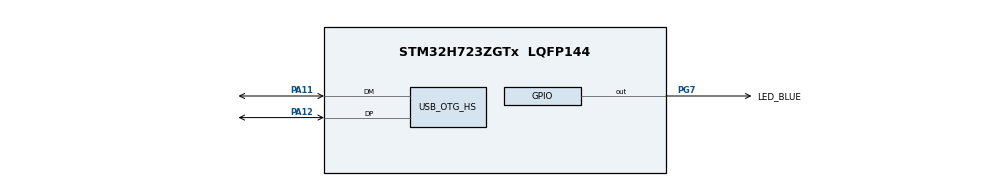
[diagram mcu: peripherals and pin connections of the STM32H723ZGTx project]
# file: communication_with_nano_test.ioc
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CORTEX_M7.default_mode_Activation=1
Mcu.Family=STM32H7
Mcu.Name=STM32H723ZGTx
Mcu.Package=LQFP144
NVIC.OTG_HS_IRQn=true\:0\:0\:false\:false\:true\:true\:true\:true
NVIC.PriorityGroup=NVIC_PRIORITYGROUP_4
NVIC.TIM6_DAC_IRQn=true\:0\:0\:false\:false\:true\:true\:true\:true
PA11.Mode=Device_Only_FS
PA11.Signal=USB_OTG_HS_DM
PA12.Mode=Device_Only_FS
PA12.Signal=USB_OTG_HS_DP
PA13(JTMS/SWDIO).Mode=Serial_Wire
PA13(JTMS/SWDIO).Signal=DEBUG_JTMS-SWDIO
PA14(JTCK/SWCLK).Mode=Serial_Wire
PA14(JTCK/SWCLK).Signal=DEBUG_JTCK-SWCLK
PC14-OSC32_IN.Mode=LSE-External-Oscillator
PC14-OSC32_IN.Signal=RCC_OSC32_IN
PC15-OSC32_OUT.Mode=LSE-External-Oscillator
PC15-OSC32_OUT.Signal=RCC_OSC32_OUT
PG7.GPIO_Label=LED_BLUE
PG7.PinState=GPIO_PIN_SET
PG7.Signal=GPIO_Output
PH0-OSC_IN.Mode=HSE-External-Oscillator
PH0-OSC_IN.Signal=RCC_OSC_IN
PH1-OSC_OUT.Mode=HSE-External-Oscillator
PH1-OSC_OUT.Signal=RCC_OSC_OUT
ProjectManager.HeapSize=0x200
ProjectManager.StackSize=0x400
ProjectManager.TargetToolchain=STM32CubeIDE
RCC.ADCFreq_Value=50390625
RCC.APB1Freq_Value=120000000
RCC.APB2Freq_Value=120000000
RCC.APB3Freq_Value=120000000
RCC.APB4Freq_Value=120000000
RCC.CortexFreq_Value=240000000
RCC.D1PPRE=RCC_APB3_DIV2
RCC.D2PPRE1=RCC_APB1_DIV2
RCC.D2PPRE2=RCC_APB2_DIV2
RCC.D3PPRE=RCC_APB4_DIV2
RCC.DIVM1=5
RCC.DIVN1=48
RCC.DIVP1=1
RCC.DIVQ1=5
RCC.HCLKFreq_Value=240000000
RCC.PLL2FRACN=0
RCC.PLL3FRACN=0
RCC.PLLFRACN=0
RCC.PLLSourceVirtual=RCC_PLLSOURCE_HSE
RCC.SYSCLKFreq_VALUE=240000000
RCC.SYSCLKSource=RCC_SYSCLKSOURCE_PLLCLK
RCC.USBFreq_Value=48000000
TIM6.Period=999
TIM6.Prescaler=239
USB_DEVICE.CLASS_NAME_HS=CDC
USB_DEVICE.VirtualMode=Cdc
USB_DEVICE.VirtualModeHS=Cdc_HS
USB_OTG_HS.VirtualMode-Device_Only_FS=Device_Only_FS
VP_MEMORYMAP_VS_MEMORYMAP.Mode=CurAppReg
VP_TIM6_VS_ClockSourceINT.Mode=Enable_Timer
VP_USB_DEVICE_VS_USB_DEVICE_CDC_HS.Mode=CDC_HS
board=custom

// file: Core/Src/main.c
/* USER CODE BEGIN Header */
/**
  ******************************************************************************
  * @file           : main.c
  * @brief          : Main program body
  ******************************************************************************
  * @attention
  *
  * Copyright (c) 2026 STMicroelectronics.
  * All rights reserved.
  *
  * This software is licensed under terms that can be found in the LICENSE file
  * in the root directory of this software component.
  * If no LICENSE file comes with this software, it is provided AS-IS.
  *
  ******************************************************************************
  */
/* USER CODE END Header */
#include "main.h"
#include "tim.h"
#include "usb_device.h"
#include "gpio.h"

/* USER CODE BEGIN Includes */
#include "fk723_robot_app.h"
/* USER CODE END Includes */

void SystemClock_Config(void);
static void MPU_Config(void);

int main(void)
{

  /* USER CODE BEGIN 1 */
	SCB_EnableICache();
	SCB_EnableDCache();
  /* USER CODE END 1 */

  /* MPU Configuration--------------------------------------------------------*/
  MPU_Config();

  /* MCU Configuration--------------------------------------------------------*/

  /* Reset of all peripherals, Initializes the Flash interface and the Systick. */
  HAL_Init();

  /* Configure the system clock */
  SystemClock_Config();

  /* Initialize all configured peripherals */
  MX_GPIO_Init();
  MX_TIM6_Init();
  MX_USB_DEVICE_Init();
  /* USER CODE BEGIN 2 */
  RobotApp_Init();
  /* USER CODE END 2 */

  /* Infinite loop */
  /* USER CODE BEGIN WHILE */
  while (1)
  {
	RobotApp_MainLoop();
    /* USER CODE END WHILE */

  }
}

void SystemClock_Config(void)
{
  RCC_OscInitTypeDef RCC_OscInitStruct = {0};
  RCC_ClkInitTypeDef RCC_ClkInitStruct = {0};

  /** Supply configuration update enable
  */
  HAL_PWREx_ConfigSupply(PWR_LDO_SUPPLY);

  /** Configure the main internal regulator output voltage
  */
  __HAL_PWR_VOLTAGESCALING_CONFIG(PWR_REGULATOR_VOLTAGE_SCALE0);

  while(!__HAL_PWR_GET_FLAG(PWR_FLAG_VOSRDY)) {}

  /** Initializes the RCC Oscillators according to the specified parameters
  * in the RCC_OscInitTypeDef structure.
  */
  RCC_OscInitStruct.OscillatorType = RCC_OSCILLATORTYPE_HSE;
  RCC_OscInitStruct.HSEState = RCC_HSE_ON;
  RCC_OscInitStruct.PLL.PLLState = RCC_PLL_ON;
  RCC_OscInitStruct.PLL.PLLSource = RCC_PLLSOURCE_HSE;
  RCC_OscInitStruct.PLL.PLLM = 5;
  RCC_OscInitStruct.PLL.PLLN = 48;
  RCC_OscInitStruct.PLL.PLLP = 1;
  RCC_OscInitStruct.PLL.PLLQ = 5;
  RCC_OscInitStruct.PLL.PLLR = 2;
  RCC_OscInitStruct.PLL.PLLRGE = RCC_PLL1VCIRANGE_2;
  RCC_OscInitStruct.PLL.PLLVCOSEL = RCC_PLL1VCOWIDE;
  RCC_OscInitStruct.PLL.PLLFRACN = 0;
  if (HAL_RCC_OscConfig(&RCC_OscInitStruct) != HAL_OK)
  {
    Error_Handler();
  }

  /** Initializes the CPU, AHB and APB buses clocks
  */
  RCC_ClkInitStruct.ClockType = RCC_CLOCKTYPE_HCLK|RCC_CLOCKTYPE_SYSCLK
                              |RCC_CLOCKTYPE_PCLK1|RCC_CLOCKTYPE_PCLK2
                              |RCC_CLOCKTYPE_D3PCLK1|RCC_CLOCKTYPE_D1PCLK1;
  RCC_ClkInitStruct.SYSCLKSource = RCC_SYSCLKSOURCE_PLLCLK;
  RCC_ClkInitStruct.SYSCLKDivider = RCC_SYSCLK_DIV1;
  RCC_ClkInitStruct.AHBCLKDivider = RCC_HCLK_DIV1;
  RCC_ClkInitStruct.APB3CLKDivider = RCC_APB3_DIV2;
  RCC_ClkInitStruct.APB1CLKDivider = RCC_APB1_DIV2;
  RCC_ClkInitStruct.APB2CLKDivider = RCC_APB2_DIV2;
  RCC_ClkInitStruct.APB4CLKDivider = RCC_APB4_DIV2;

  if (HAL_RCC_ClockConfig(&RCC_ClkInitStruct, FLASH_LATENCY_3) != HAL_OK)
  {
    Error_Handler();
  }
}

 /* MPU Configuration */

void MPU_Config(void)
{
  MPU_Region_InitTypeDef MPU_InitStruct = {0};

  /* Disables the MPU */
  HAL_MPU_Disable();

  /** Initializes and configures the Region and the memory to be protected
  */
  MPU_InitStruct.Enable = MPU_REGION_ENABLE;
  MPU_InitStruct.Number = MPU_REGION_NUMBER0;
  MPU_InitStruct.BaseAddress = 0x0;
  MPU_InitStruct.Size = MPU_REGION_SIZE_4GB;
  MPU_InitStruct.SubRegionDisable = 0x87;
  MPU_InitStruct.TypeExtField = MPU_TEX_LEVEL0;
  MPU_InitStruct.AccessPermission = MPU_REGION_NO_ACCESS;
  MPU_InitStruct.DisableExec = MPU_INSTRUCTION_ACCESS_DISABLE;
  MPU_InitStruct.IsShareable = MPU_ACCESS_SHAREABLE;
  MPU_InitStruct.IsCacheable = MPU_ACCESS_NOT_CACHEABLE;
  MPU_InitStruct.IsBufferable = MPU_ACCESS_NOT_BUFFERABLE;

  HAL_MPU_ConfigRegion(&MPU_InitStruct);
  /* Enables the MPU */
  HAL_MPU_Enable(MPU_PRIVILEGED_DEFAULT);

}

void Error_Handler(void)
{
  __disable_irq();
  while (1)
  {
  }
}
